# A31G22x register map
Vendor: ABOV Semiconductor Co., Ltd.; Series: A31G22x; File version: 0.2
CPU: CM0PLUS r0p1, little endian, no MPU, no FPU, VTOR, 2 interrupt priority bits
Registers are 32-bit, read-write, reset 0x0 unless marked. A register's access mark holds for its fields unless they carry their own. Offsets are from the block's base; [hi:lo] are bit positions.

## CFMC — CODE FLASH MEMORY CONTROLLER
Base 0x40000100
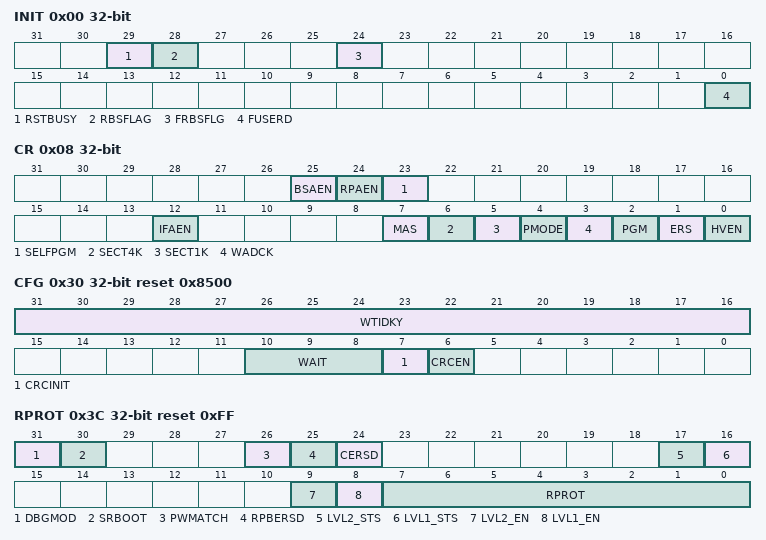
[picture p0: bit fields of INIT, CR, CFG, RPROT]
0x00 INIT — Code Flash Memory INIT Register
  [29] RSTBUSY — RSTBUSY status bit - sychronized with PCLK
  [28] RBSFLAG — 1st RSTBUSY flag bit
  [24] FRBSFLG — 2nd RSTBUSY flag bit
  [0] FUSERD — Fuse read bit. this bit must be set before DCT read in BootROM mode.
0x04 MR — Code Flash Memory Mode Register
  [6:0] ACODE — Access Code. 5A->A5 : Flash mode entry A5->5A : Trim mode entry 81->28 : AMBA mode entry 66->99 : PROT mode entry
0x08 CR — Code Flash Memory Control Register
  [25] BSAEN — Bank selection block access enable
  [24] RPAEN — Read protection block access enable
  [23] SELFPGM — When this bit is set(1), PGM/ERS/HVEN will be cleared automatically after WRBUSY falling edge. It also enable CPU wait control when HVEN bit is set(1) (start of program or erase operation)It also affects to PMODE bit operation.
  [12] IFAEN — Info(User Data0, User Data1, User Data2) block access enable
  [7] MAS — Mass(bulk) erase enable
  [6] SECT4K — Sector 4K erase enable
  [5] SECT1K — Sector 1K erase enable
  [4] PMODE — PMODE enable (Flash Address path is connected with FMAR) PMODE only valid when SELFPGM bit was not set(when SELFPGM = 0)
  [3] WADCK — Program/Erase address data latch clock enable
  [2] PGM — Program mode enable
  [1] ERS — Erase mode enable
  [0] HVEN — High Voltage cycle enable
0x0C AR — Code Flash Memory Address Register
  [15:0] FADDR — Word(32-bit) base address : 64K-word address for 256KB Flash. Auto Incremental after WADCK trigger (after latching of target address).
0x10 DR — Code Flash Memory Data Register
  [31:0] FDATA — Word size(32-bit) data
0x18 BUSY — Code Flash Memory Write Busy Status Register
  [0] WRBUSY — Write Busy status bit FLBUSY bit goes high after set HVEN bit (in CTRL register). FLBUSY bit goes low when WRBUSY becomes low after program(or erase) complete.
0x20 CRCCCITT — Code Flash Memory CRC-CCITT Check Register
  [15:0] CRC — CRC-CCITT check value read register polynomial: (1 + x5 + x12 + x16) data width: 32 (the first serial bit is D[31])
0x30 CFG reset 0x8500 — Code Flash Memory Config Register
  [31:16] WTIDKY — Write Identification Key. On writes, write 0x7858 to these bits, otherwise the write is ignored.
  [10:8] WAIT — This bits only be written in AMBA mode and MSB 16-bit (bit [31:16]) must be 0x7858 000 : flash access in 1 cycle (0-wait) / 001 : flash access in 2 cycles (1-wait) / 010 : flash access in 3 cycles (2-wait) - default / 011, flash access in 4 cycles (3-wait) 100, flash access in 5 cycles (4-wait) 101, flash access in 6 cycles (5-wait)
  [7] CRCINIT — When this bit is set('1'), CRC register will be initialized It should be reset again before read flash to generate CRC-CCITT calculation (Initial value of FMCRC is 0xFFFF)
  [6] CRCEN — CRC-CCITT enable CRC value will be calculated at every flash read timing
0x34 WPROT — Flash Memory Write Protection Register
  [15:0] WPROT — Write protection each 16 KB segments for whole memory address (needs 16 bits for 256KB flash)
0x3C RPROT reset 0xFF — Code Flash Memory Read Protection Register
  [31] DBGMOD ro — Debug Operating Status bit
  [30] SRBOOT ro — SRAM Boot Mode Status bit
  [26] PWMATCH ro — Password Match Flag bit
  [25] RPBERSD ro — Chip Erase and Read Protection Block Erase Done Flag bit
  [24] CERSD ro — Chip Erase Done Flag bit
  [17] LVL2_STS ro — Protection Level 2 Status bit (raw data)
  [16] LVL1_STS ro — Protection Level 1 Status bit (raw data)
  [9] LVL2_EN ro — Protection Level 2 Enable Status bit
  [8] LVL1_EN ro — Protection Level 1 Enable Status bit
  [7:0] RPROT — Read protection 0xff : Unprotection 0x39 : Protection Level 1 others : Protection Level 2 When the memory is in either protection mode, setting the 8th bit to 1 enables the password function for the protection mode
0x40 PWIN wo — Code Flash Memory Password Input Register
  [31:0] PWIN — Password input data bit
0x44 PWPRST wo — Code Flash Memory Password Preset Register
  [31:0] PWPRST — Password preset data bit
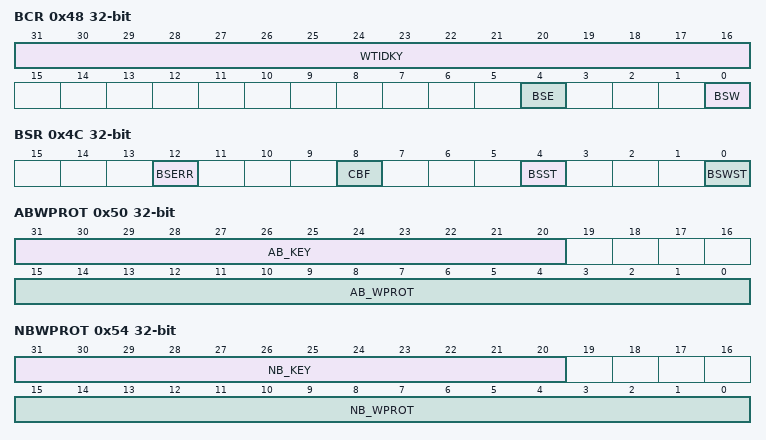
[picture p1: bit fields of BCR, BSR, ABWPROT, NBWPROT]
0x48 BCR — Code Flash Memory Bank Control Register
  [31:16] WTIDKY wo — Write Identification Key. On writes, write 0xAA91 to these bits, otherwise the write is ignored.
  [4] BSE — Memory Bank Selection Enable bit for swap operation
  [0] BSW — Bank Swap
0x4C BSR — Code Flash Memory Bank Status Register
  [12] BSERR — Error handling flag bit for Bank Selection
  [8] CBF — Current Boot bank flag bit
  [4] BSST ro — Bank Selection Status bit
  [0] BSWST ro — Bank Swap Status bit
0x50 ABWPROT — Code Flash Memory Active Bootloader Area Write Protection Register
  [31:20] AB_KEY wo — Write protection key value 0xAAB for the active bootloader area
  [15:0] AB_WPROT — 1KB write protection of user bootloader area in active bank
0x54 NBWPROT — Code Flash Memory Non-active Bootloader Area Write Protection Register
  [31:20] NB_KEY wo — Write protection key value 0x55B for the non-active bootloader area
  [15:0] NB_WPROT — 1KB write protection of user bootloader area in non-active bank
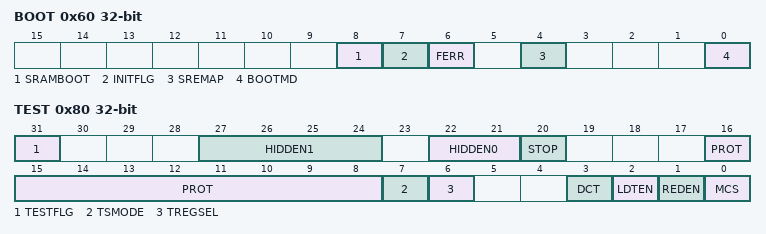
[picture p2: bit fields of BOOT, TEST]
0x60 BOOT — Code Flash Memory Boot Register
  [8] SRAMBOOT — SRAM Boot mode bit
  [7] INITFLG — Code Flash Initialize for debug
  [6] FERR — Code Flash Error bit for debug
  [4] SREMAP — SRAM Re-Map enable bit
  [0] BOOTMD ro — Bootloader mode bit
0x64 TMR — Code Flash Memory Timer Counter Register
  [19:0] TIMER — Code Flash Timer Counter
0x68 TICK — Code Flash Memory Tick Timer Register
  [19:0] TICK — Code Flash Tick Timer
0x80 TEST — Code Flash Memory TEST Register
  [31] TESTFLG — Test Flash
  [27:24] HIDDEN1 — Hidden Test Enable 1
  [22:21] HIDDEN0 — Hidden Test Enable 0
  [20] STOP — Flash Stop bit control
  [16:8] PROT — PROT[8:0] area access enable
  [7] TSMODE — TSMODE set
  [6] TREGSEL — TREG selection (test register in flash IP)
  [3] DCT — DCT area access enable bit
  [2] LDTEN — LDT area access enable bit
  [1] REDEN — RED area access enable bit
  [0] MCS — MCS control bit
0x84 HWID — Code Flash Memory Hardware ID Register
0x88 SIZE — Code Flash Memory Size Register
0x90 DCT0 ro — Code Flash Memory DCT0 Register
0x94 DCT1 ro — Code Flash Memory DCT0 Register
